# M3351 register map
File version: 1.0
Registers are 32-bit, read-write, reset 0x0 unless marked. A register's access mark holds for its fields unless they carry their own. Offsets are from the block's base; [hi:lo] are bit positions; 'fields as' and 'values as' point back to an identical list.

## NMI — NMI Register Map
Base 0x40000300
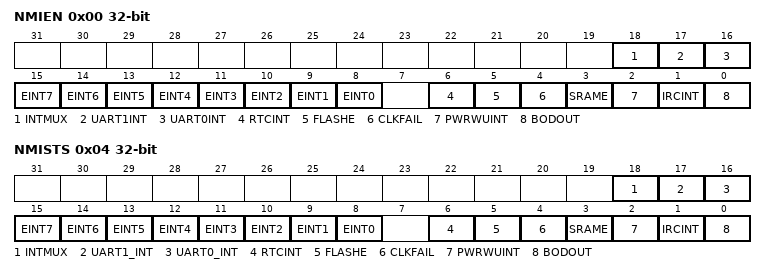
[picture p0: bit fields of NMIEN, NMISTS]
0x00 NMIEN — NMI Source Interrupt Enable Register
  [18] INTMUX — NMI Multiplexer Source Enable (Write Protect). Note: This bit is write protected. Refer to the SYS_REGLCTL register.
    0=NMI multiplexer source Disabled; 1=NMI multiplexer source Enabled
  [17] UART1INT — UART1 NMI Source Enable (Write Protect). Note: This bit is write protected. Refer to the SYS_REGLCTL register.
    0=UART1 NMI source Disabled; 1=UART1 NMI source Enabled
  [16] UART0INT — UART0 NMI Source Enable (Write Protect). Note: This bit is write protected. Refer to the SYS_REGLCTL register.
    0=UART0 NMI source Disabled; 1=UART0 NMI source Enabled
  [15] EINT7 — External Interrupt from INT7 Pins NMI Source Enable (Write Protect). Note: This bit is write protected. Refer to the SYS_REGLCTL register.
    0=External interrupt from INT7(PD.10) pins NMI source Disabled; 1=External interrupt from INT7(PD.10) pins NMI source Enabled
  [14] EINT6 — External Interrupt from INT6 Pins NMI Source Enable (Write Protect). Note: This bit is write protected. Refer to the SYS_REGLCTL register.
    0=External interrupt from INT6(PD.11) pins NMI source Disabled; 1=External interrupt from INT6(PD.11) pins NMI source Enabled
  [13] EINT5 — External Interrupt from INT5 Pins NMI Source Enable (Write Protect). Note: This bit is write protected. Refer to the SYS_REGLCTL register.
    0=External interrupt from INT5(PD.12) pins NMI source Disabled; 1=External interrupt from INT5(PD.12) pins NMI source Enabled
  [12] EINT4 — External Interrupt from INT4 Pins NMI Source Enable (Write Protect). Note: This bit is write protected. Refer to the SYS_REGLCTL register.
    0=External interrupt from INT4(PA.8) pins NMI source Disabled; 1=External interrupt from INT4(PA.8) pins NMI source Enabled
  [11] EINT3 — External Interrupt from INT3 Pins NMI Source Enable (Write Protect). Note: This bit is write protected. Refer to the SYS_REGLCTL register.
    0=External interrupt from INT3(PB.2) pins NMI source Disabled; 1=External interrupt from INT3(PB.2) pins NMI source Enabled
  [10] EINT2 — External Interrupt from INT2 Pins NMI Source Enable (Write Protect). Note: This bit is write protected. Refer to the SYS_REGLCTL register.
    0=External interrupt from INT2(PB.3) pins NMI source Disabled; 1=External interrupt from INT2(PB.3) pins NMI source Enabled
  [9] EINT1 — External Interrupt from INT1 Pins NMI Source Enable (Write Protect). Note: This bit is write protected. Refer to the SYS_REGLCTL register.
    0=External interrupt from INT1(PB.4) pins NMI source Disabled; 1=External interrupt from INT1(PB.4) pins NMI source Enabled
  [8] EINT0 — External Interrupt from INT0 Pins NMI Source Enable (Write Protect). Note: This bit is write protected. Refer to the SYS_REGLCTL register.
    0=External interrupt from INT0(PB.5) pins NMI source Disabled; 1=External interrupt from INT0(PB.5) pins NMI source Enabled
  [6] RTCINT — RTC NMI Source Enable (Write Protect). Note: This bit is write protected. Refer to the SYS_REGLCTL register.
    0=RTC NMI source Disabled; 1=RTC NMI source Enabled
  [5] FLASHE — FLASH ECC Check Error NMI Source Enable (Write Protect). Note: This bit is write protected. Refer to the SYS_REGLCTL register.
    0=FLASH ECC check error NMI source Disabled; 1=FLASH ECC check error NMI source Enabled
  [4] CLKFAIL — Clock Fail Detected NMI Source Enable (Write Protect). Note: This bit is write protected. Refer to the SYS_REGLCTL register.
    0=Clock fail detected interrupt NMI source Disabled; 1=Clock fail detected interrupt NMI source Enabled
  [3] SRAME — SRAM ECC Check Error NMI Source Enable (Write Protect). Note: This bit is write protected. Refer to the SYS_REGLCTL register.
    0=SRAM ECC check error NMI source Disabled; 1=SRAM ECC check error NMI source Enabled
  [2] PWRWUINT — Power-down Mode Wake-up NMI Source Enable (Write Protect). Note: This bit is write protected. Refer to the SYS_REGLCTL register.
    0=Power-down mode wake-up NMI source Disabled; 1=Power-down mode wake-up NMI source Enabled
  [1] IRCINT — IRC TRIM NMI Source Enable (Write Protect). Note: This bit is write protected. Refer to the SYS_REGLCTL register.
    0=IRC TRIM NMI source Disabled; 1=IRC TRIM NMI source Enabled
  [0] BODOUT — BOD NMI Source Enable (Write Protect). Note: This bit is write protected. Refer to the SYS_REGLCTL register.
    0=BOD NMI source Disabled; 1=BOD NMI source Enabled
0x04 NMISTS ro — NMI Source Interrupt Status Register
  [18] INTMUX — NMI Multiple source Interrupt Flag (Read Only)
    0=NMI Multiple source Interrupt is deasserted; 1=NMI Multiple source Interrupt is asserted
  [17] UART1_INT — UART1 Interrupt Flag (Read Only)
    0=UART1 interrupt is deasserted; 1=UART1 interrupt is asserted
  [16] UART0_INT — UART0 Interrupt Flag (Read Only)
    values as UART1_INT
  [15] EINT7 — External Interrupt from INT7 Pins Interrupt Flag (Read Only)
    0=External Interrupt from INT7(PD.10) interrupt is deasserted; 1=External Interrupt from INT7(PD.10) interrupt is asserted
  [14] EINT6 — External Interrupt from INT6 Pins Interrupt Flag (Read Only)
    0=External Interrupt from INT6(PD.11) interrupt is deasserted; 1=External Interrupt from INT6(PD.11) interrupt is asserted
  [13] EINT5 — External Interrupt from INT5 Pins Interrupt Flag (Read Only)
    0=External Interrupt from INT5(PD.12) interrupt is deasserted; 1=External Interrupt from INT5(PD.12) interrupt is asserted
  [12] EINT4 — External Interrupt from INT4 Pins Interrupt Flag (Read Only)
    0=External Interrupt from INT4(PA.8) interrupt is deasserted; 1=External Interrupt from INT4(PA.8) interrupt is asserted
  [11] EINT3 — External Interrupt from INT3 Pins Interrupt Flag (Read Only)
    0=External Interrupt from INT3(PB.2) interrupt is deasserted; 1=External Interrupt from INT3(PB.2) interrupt is asserted
  [10] EINT2 — External Interrupt from INT2 Pins Interrupt Flag (Read Only)
    0=External Interrupt from INT2(PB.3) interrupt is deasserted; 1=External Interrupt from INT2(PB.3) interrupt is asserted
  [9] EINT1 — External Interrupt from INT1 Pins Interrupt Flag (Read Only)
    0=External Interrupt from INT1(PB.4) interrupt is deasserted; 1=External Interrupt from INT1(PB.4) interrupt is asserted
  [8] EINT0 — External Interrupt from INT0 Pins Interrupt Flag (Read Only)
    0=External Interrupt from INT0(PB.5) interrupt is deasserted; 1=External Interrupt from INT0(PB.5) interrupt is asserted
  [6] RTCINT — RTC Interrupt Flag (Read Only)
    0=RTC interrupt is deasserted; 1=RTC interrupt is asserted
  [5] FLASHE — FLASH ECC Check Error Interrupt Flag (Read Only)
    0=FLASH ECC check error interrupt is deasserted; 1=FLASH ECC check error interrupt is asserted
  [4] CLKFAIL — Clock Fail Detected Interrupt Flag (Read Only)
    0=Clock fail detected interrupt is deasserted; 1=Clock fail detected interrupt is asserted
  [3] SRAME — SRAM ECC Check Error Interrupt Flag (Read Only)
    0=SRAM ECC check error interrupt is deasserted; 1=SRAM ECC check error interrupt is asserted
  [2] PWRWUINT — Power-down Mode Wake-up Interrupt Flag (Read Only)
    0=Power-down mode wake-up interrupt is deasserted; 1=Power-down mode wake-up interrupt is asserted
  [1] IRCINT — IRC TRIM Interrupt Flag (Read Only)
    0=IRC TRIM interrupt is deasserted; 1=IRC TRIM interrupt is asserted
  [0] BODOUT — BOD Interrupt Flag (Read Only)
    0=BOD interrupt is deasserted; 1=BOD interrupt is asserted
0x08 NMIMSEL — NMI Multiplexer Source Select Control Register
  [7:0] NMIMSEL — NMI Multiplexer Source Selection. This bit field is to select NMI interrupt INTMUX from one of IRQ. Note: Please refer to Table 6.210.
